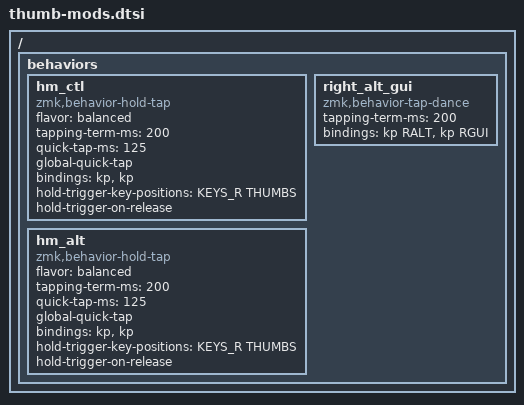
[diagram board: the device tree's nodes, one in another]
// Thumb hold-tap behaviors for the new AZERTY/QWERTY layout
// These use the KEYS_L/KEYS_R/THUMBS defined in hold-tap.dtsi

// hm_ctl = hold LCTL / tap Space
ZMK_HOLD_TAP(hm_ctl,
    flavor = "balanced";
    tapping-term-ms = <200>;
    quick-tap-ms = <125>;
    global-quick-tap;
    bindings = <&kp>, <&kp>;
    hold-trigger-key-positions = <KEYS_R THUMBS>;
    hold-trigger-on-release;
)

// hm_alt = hold LALT / tap Backspace
ZMK_HOLD_TAP(hm_alt,
    flavor = "balanced";
    tapping-term-ms = <200>;
    quick-tap-ms = <125>;
    global-quick-tap;
    bindings = <&kp>, <&kp>;
    hold-trigger-key-positions = <KEYS_R THUMBS>;
    hold-trigger-on-release;
)

// right_alt_gui — tap once = RALT, tap twice = RGUI (Windows key)
/ {
    behaviors {
        right_alt_gui: right_alt_gui {
            compatible = "zmk,behavior-tap-dance";
            #binding-cells = <0>;
            tapping-term-ms = <200>;
            bindings = <&kp RALT>, <&kp RGUI>;
        };
    };
};
